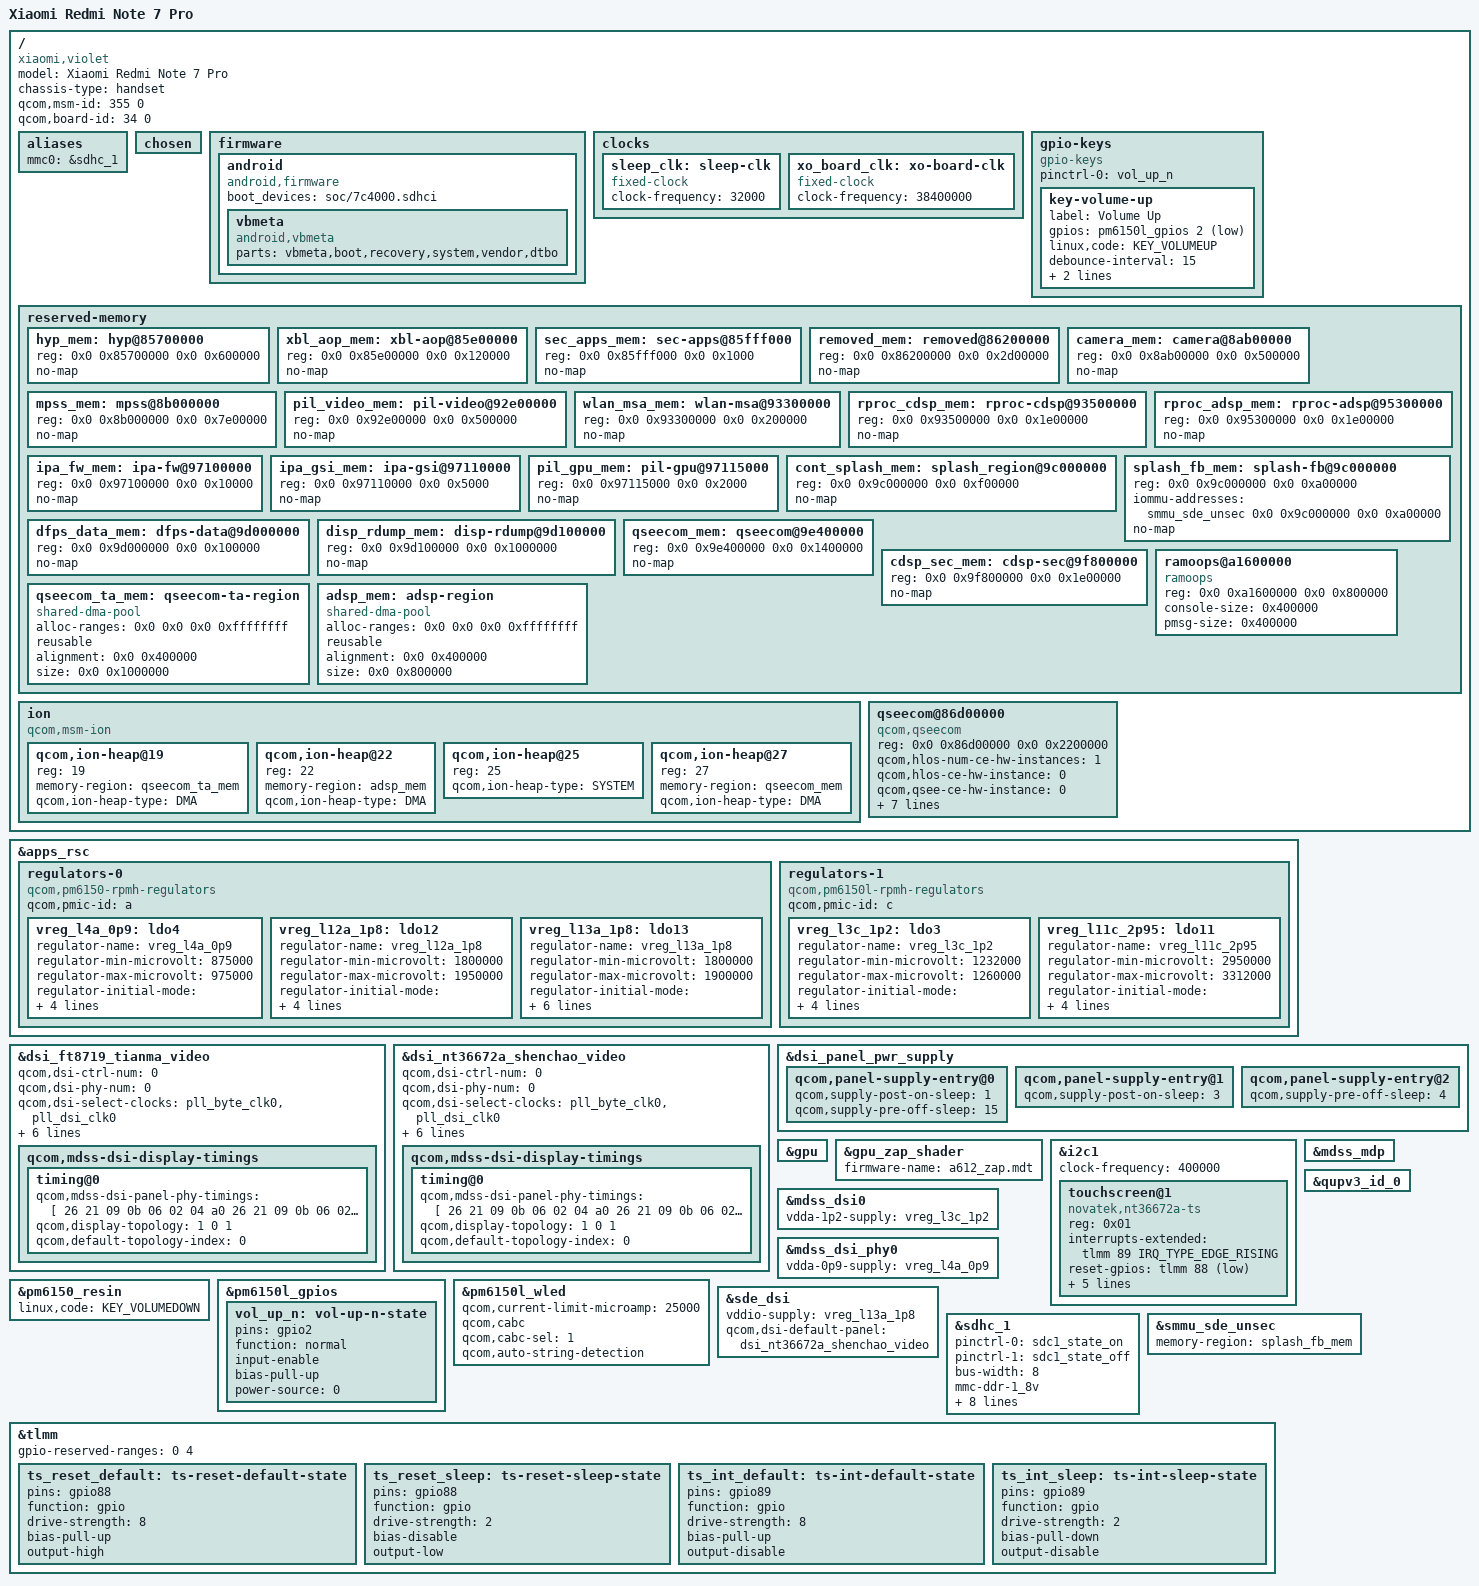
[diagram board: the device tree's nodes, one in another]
// SPDX-License-Identifier: BSD-3-Clause
/*
 * Xiaomi Redmi Note 7 Pro (violet)
 */

/dts-v1/;

#include <dt-bindings/gpio/gpio.h>
#include <dt-bindings/input/linux-event-codes.h>
#include <dt-bindings/regulator/qcom,rpmh-regulator.h>
#include "sm6150.dtsi"
#include "pm6150.dtsi"
#include "pm6150l.dtsi"
#include "sm6150-sde.dtsi"
#include "dsi-panel-ft8719-tianma-fhd-video.dtsi"
#include "dsi-panel-nt36672a-shenchao-fhd-video.dtsi"

/*
 * The GPU, video, CDSP and ADSP firmware regions sit lower on violet than on
 * QCS615; they are re-added below at the addresses violet's firmware uses.
 */
/delete-node/ &pil_gpu_mem;
/delete-node/ &pil_video_mem;
/delete-node/ &rproc_cdsp_mem;
/delete-node/ &rproc_adsp_mem;

/ {
	model = "Xiaomi Redmi Note 7 Pro";
	compatible = "xiaomi,violet", "qcom,sm6150";
	chassis-type = "handset";

	/* The msm-4.14 bootloader picks the DTB by these */
	qcom,msm-id = <355 0>;
	qcom,board-id = <34 0>;

	aliases {
		mmc0 = &sdhc_1;
	};

	chosen {
	};

	firmware {
		android {
			compatible = "android,firmware";
			boot_devices = "soc/7c4000.sdhci";

			vbmeta {
				compatible = "android,vbmeta";
				parts = "vbmeta,boot,recovery,system,vendor,dtbo";
			};
		};
	};

	clocks {
		sleep_clk: sleep-clk {
			compatible = "fixed-clock";
			clock-frequency = <32000>;
			#clock-cells = <0>;
		};

		xo_board_clk: xo-board-clk {
			compatible = "fixed-clock";
			clock-frequency = <38400000>;
			#clock-cells = <0>;
		};
	};

	gpio-keys {
		compatible = "gpio-keys";

		pinctrl-0 = <&vol_up_n>;
		pinctrl-names = "default";

		key-volume-up {
			label = "Volume Up";
			gpios = <&pm6150l_gpios 2 GPIO_ACTIVE_LOW>;
			linux,code = <KEY_VOLUMEUP>;
			debounce-interval = <15>;
			linux,can-disable;
			wakeup-source;
		};
	};

	reserved-memory {
		hyp_mem: hyp@85700000 {
			reg = <0x0 0x85700000 0x0 0x600000>;
			no-map;
		};

		xbl_aop_mem: xbl-aop@85e00000 {
			reg = <0x0 0x85e00000 0x0 0x120000>;
			no-map;
		};

		sec_apps_mem: sec-apps@85fff000 {
			reg = <0x0 0x85fff000 0x0 0x1000>;
			no-map;
		};

		removed_mem: removed@86200000 {
			reg = <0x0 0x86200000 0x0 0x2d00000>;
			no-map;
		};

		camera_mem: camera@8ab00000 {
			reg = <0x0 0x8ab00000 0x0 0x500000>;
			no-map;
		};

		mpss_mem: mpss@8b000000 {
			reg = <0x0 0x8b000000 0x0 0x7e00000>;
			no-map;
		};

		pil_video_mem: pil-video@92e00000 {
			reg = <0x0 0x92e00000 0x0 0x500000>;
			no-map;
		};

		wlan_msa_mem: wlan-msa@93300000 {
			reg = <0x0 0x93300000 0x0 0x200000>;
			no-map;
		};

		rproc_cdsp_mem: rproc-cdsp@93500000 {
			reg = <0x0 0x93500000 0x0 0x1e00000>;
			no-map;
		};

		rproc_adsp_mem: rproc-adsp@95300000 {
			reg = <0x0 0x95300000 0x0 0x1e00000>;
			no-map;
		};

		ipa_fw_mem: ipa-fw@97100000 {
			reg = <0x0 0x97100000 0x0 0x10000>;
			no-map;
		};

		ipa_gsi_mem: ipa-gsi@97110000 {
			reg = <0x0 0x97110000 0x0 0x5000>;
			no-map;
		};

		pil_gpu_mem: pil-gpu@97115000 {
			reg = <0x0 0x97115000 0x0 0x2000>;
			no-map;
		};

		/*
		 * The bootloader looks this node up by name and rewrites its
		 * size to the framebuffer it leaves on screen.
		 */
		cont_splash_mem: splash_region@9c000000 {
			reg = <0x0 0x9c000000 0x0 0xf00000>;
			no-map;
		};

		/*
		 * The framebuffer the bootloader leaves on screen, mapped 1:1
		 * for the display from the moment the IOMMU takes it over.
		 */
		splash_fb_mem: splash-fb@9c000000 {
			reg = <0x0 0x9c000000 0x0 0xa00000>;
			iommu-addresses = <&smmu_sde_unsec 0x0 0x9c000000 0x0 0xa00000>;
			no-map;
		};

		dfps_data_mem: dfps-data@9d000000 {
			reg = <0x0 0x9d000000 0x0 0x100000>;
			no-map;
		};

		disp_rdump_mem: disp-rdump@9d100000 {
			reg = <0x0 0x9d100000 0x0 0x1000000>;
			no-map;
		};

		qseecom_mem: qseecom@9e400000 {
			reg = <0x0 0x9e400000 0x0 0x1400000>;
			no-map;
		};

		cdsp_sec_mem: cdsp-sec@9f800000 {
			reg = <0x0 0x9f800000 0x0 0x1e00000>;
			no-map;
		};

		ramoops@a1600000 {
			compatible = "ramoops";
			reg = <0x0 0xa1600000 0x0 0x800000>;
			console-size = <0x400000>;
			pmsg-size = <0x400000>;
		};

		qseecom_ta_mem: qseecom-ta-region {
			compatible = "shared-dma-pool";
			alloc-ranges = <0x0 0x0 0x0 0xffffffff>;
			reusable;
			alignment = <0x0 0x400000>;
			size = <0x0 0x1000000>;
		};

		adsp_mem: adsp-region {
			compatible = "shared-dma-pool";
			alloc-ranges = <0x0 0x0 0x0 0xffffffff>;
			reusable;
			alignment = <0x0 0x400000>;
			size = <0x0 0x800000>;
		};
	};

	/* /dev/ion, with the heap IDs violet's vendor HALs were built for */
	ion {
		compatible = "qcom,msm-ion";
		#address-cells = <1>;
		#size-cells = <0>;

		qcom,ion-heap@19 {
			reg = <19>;
			memory-region = <&qseecom_ta_mem>;
			qcom,ion-heap-type = "DMA";
		};

		qcom,ion-heap@22 {
			reg = <22>;
			memory-region = <&adsp_mem>;
			qcom,ion-heap-type = "DMA";
		};

		qcom,ion-heap@25 {
			reg = <25>;
			qcom,ion-heap-type = "SYSTEM";
		};

		qcom,ion-heap@27 {
			reg = <27>;
			memory-region = <&qseecom_mem>;
			qcom,ion-heap-type = "DMA";
		};
	};

	qseecom@86d00000 {
		compatible = "qcom,qseecom";
		reg = <0x0 0x86d00000 0x0 0x2200000>;
		reg-names = "secapp-region";
		qcom,hlos-num-ce-hw-instances = <1>;
		qcom,hlos-ce-hw-instance = <0>;
		qcom,qsee-ce-hw-instance = <0>;
		qcom,disk-encrypt-pipe-pair = <2>;
		qcom,support-fde;
		qcom,no-clock-support;
		qcom,fde-key-size;
		qcom,appsbl-qseecom-support;
		qcom,commonlib64-loaded-by-uefi;
		qcom,qsee-reentrancy-support = <2>;
	};
};

&apps_rsc {
	regulators-0 {
		compatible = "qcom,pm6150-rpmh-regulators";
		qcom,pmic-id = "a";

		vreg_l4a_0p9: ldo4 {
			regulator-name = "vreg_l4a_0p9";
			regulator-min-microvolt = <875000>;
			regulator-max-microvolt = <975000>;
			regulator-initial-mode = <RPMH_REGULATOR_MODE_HPM>;
			regulator-allow-set-load;
			regulator-allowed-modes = <RPMH_REGULATOR_MODE_LPM
						   RPMH_REGULATOR_MODE_HPM>;
		};

		vreg_l12a_1p8: ldo12 {
			regulator-name = "vreg_l12a_1p8";
			regulator-min-microvolt = <1800000>;
			regulator-max-microvolt = <1950000>;
			regulator-initial-mode = <RPMH_REGULATOR_MODE_HPM>;
			regulator-allow-set-load;
			regulator-allowed-modes = <RPMH_REGULATOR_MODE_LPM
						   RPMH_REGULATOR_MODE_HPM>;
		};

		/*
		 * The panel's and the touch's 1.8 V I/O, and the pull-ups of
		 * the touch I2C bus: keep it on, or the touch driver turns it
		 * off after probing, before the display has taken it.
		 */
		vreg_l13a_1p8: ldo13 {
			regulator-name = "vreg_l13a_1p8";
			regulator-min-microvolt = <1800000>;
			regulator-max-microvolt = <1900000>;
			regulator-initial-mode = <RPMH_REGULATOR_MODE_HPM>;
			regulator-boot-on;
			regulator-always-on;
			regulator-allow-set-load;
			regulator-allowed-modes = <RPMH_REGULATOR_MODE_LPM
						   RPMH_REGULATOR_MODE_HPM>;
		};
	};

	regulators-1 {
		compatible = "qcom,pm6150l-rpmh-regulators";
		qcom,pmic-id = "c";

		vreg_l3c_1p2: ldo3 {
			regulator-name = "vreg_l3c_1p2";
			regulator-min-microvolt = <1232000>;
			regulator-max-microvolt = <1260000>;
			regulator-initial-mode = <RPMH_REGULATOR_MODE_HPM>;
			regulator-allow-set-load;
			regulator-allowed-modes = <RPMH_REGULATOR_MODE_LPM
						   RPMH_REGULATOR_MODE_HPM>;
		};

		vreg_l11c_2p95: ldo11 {
			regulator-name = "vreg_l11c_2p95";
			regulator-min-microvolt = <2950000>;
			regulator-max-microvolt = <3312000>;
			regulator-initial-mode = <RPMH_REGULATOR_MODE_HPM>;
			regulator-allow-set-load;
			regulator-allowed-modes = <RPMH_REGULATOR_MODE_LPM
						   RPMH_REGULATOR_MODE_HPM>;
		};
	};
};

/*
 * The bootloader names the panel it found in msm_drm.dsi_display0=, and
 * the driver looks it up by node name, so the panel nodes keep the names
 * the bootloader knows.
 */
&dsi_ft8719_tianma_video {
	qcom,dsi-ctrl-num = <0>;
	qcom,dsi-phy-num = <0>;
	qcom,dsi-select-clocks = "pll_byte_clk0", "pll_dsi_clk0";

	qcom,mdss-dsi-t-clk-post = <0x0f>;
	qcom,mdss-dsi-t-clk-pre = <0x37>;
	qcom,panel-supply-entries = <&dsi_panel_pwr_supply>;
	qcom,platform-te-gpio = <&tlmm 90 0>;
	qcom,platform-reset-gpio = <&tlmm 91 0>;

	qcom,mdss-dsi-display-timings {
		timing@0 {
			qcom,mdss-dsi-panel-phy-timings = [
				26 21 09 0b 06 02 04 a0
				26 21 09 0b 06 02 04 a0
				26 21 09 0b 06 02 04 a0
				26 21 09 0b 06 02 04 a0
				26 20 0a 0b 06 02 04 a0];
			qcom,display-topology = <1 0 1>;
			qcom,default-topology-index = <0>;
		};
	};
};

&dsi_nt36672a_shenchao_video {
	qcom,dsi-ctrl-num = <0>;
	qcom,dsi-phy-num = <0>;
	qcom,dsi-select-clocks = "pll_byte_clk0", "pll_dsi_clk0";

	qcom,mdss-dsi-t-clk-post = <0x0f>;
	qcom,mdss-dsi-t-clk-pre = <0x37>;
	qcom,panel-supply-entries = <&dsi_panel_pwr_supply>;
	qcom,platform-te-gpio = <&tlmm 90 0>;
	qcom,platform-reset-gpio = <&tlmm 91 0>;

	qcom,mdss-dsi-display-timings {
		timing@0 {
			qcom,mdss-dsi-panel-phy-timings = [
				26 21 09 0b 06 02 04 a0
				26 21 09 0b 06 02 04 a0
				26 21 09 0b 06 02 04 a0
				26 21 09 0b 06 02 04 a0
				26 20 0a 0b 06 02 04 a0];
			qcom,display-topology = <1 0 1>;
			qcom,default-topology-index = <0>;
		};
	};
};

/*
 * The panel power entries keep the lab and ibb names, but nothing drives
 * the PM6150L LCDB yet: those two fall back to dummy supplies, and the
 * LCDB stays on as the bootloader left it.
 */
&dsi_panel_pwr_supply {
	qcom,panel-supply-entry@0 {
		qcom,supply-post-on-sleep = <1>;
		qcom,supply-pre-off-sleep = <15>;
	};

	qcom,panel-supply-entry@1 {
		qcom,supply-post-on-sleep = <3>;
	};

	qcom,panel-supply-entry@2 {
		/delete-property/ qcom,supply-post-on-sleep;
		qcom,supply-pre-off-sleep = <4>;
	};
};

&gpu {
	status = "okay";
};

&gpu_zap_shader {
	/* The vendor partition has the zap shader split into segments */
	firmware-name = "a612_zap.mdt";
};

&i2c1 {
	clock-frequency = <400000>;
	status = "okay";

	/* The touch part of the NT36672A TDDI on the Shenchao panel */
	touchscreen@1 {
		compatible = "novatek,nt36672a-ts";
		reg = <0x01>;

		interrupts-extended = <&tlmm 89 IRQ_TYPE_EDGE_RISING>;
		reset-gpios = <&tlmm 88 GPIO_ACTIVE_LOW>;

		iovcc-supply = <&vreg_l13a_1p8>;

		pinctrl-0 = <&ts_int_default &ts_reset_default>;
		pinctrl-1 = <&ts_int_sleep &ts_reset_sleep>;
		pinctrl-names = "default", "sleep";

		touchscreen-size-x = <1080>;
		touchscreen-size-y = <2340>;
	};
};

&mdss_dsi0 {
	vdda-1p2-supply = <&vreg_l3c_1p2>;
	status = "okay";
};

&mdss_dsi_phy0 {
	vdda-0p9-supply = <&vreg_l4a_0p9>;
	status = "okay";
};

&mdss_mdp {
	status = "okay";
};

&pm6150_resin {
	linux,code = <KEY_VOLUMEDOWN>;
	status = "okay";
};

&pm6150l_gpios {
	vol_up_n: vol-up-n-state {
		pins = "gpio2";
		function = "normal";
		input-enable;
		bias-pull-up;
		power-source = <0>;
	};
};

&pm6150l_wled {
	qcom,current-limit-microamp = <25000>;
	qcom,cabc;
	qcom,cabc-sel = <1>;
	qcom,auto-string-detection;

	status = "okay";
};

&qupv3_id_0 {
	status = "okay";
};

&sde_dsi {
	vddio-supply = <&vreg_l13a_1p8>;

	/* Used when the bootloader does not name the panel */
	qcom,dsi-default-panel = <&dsi_nt36672a_shenchao_video>;

	status = "okay";
};

&sdhc_1 {
	pinctrl-0 = <&sdc1_state_on>;
	pinctrl-1 = <&sdc1_state_off>;
	pinctrl-names = "default", "sleep";

	bus-width = <8>;
	mmc-ddr-1_8v;
	mmc-hs200-1_8v;
	mmc-hs400-1_8v;
	mmc-hs400-enhanced-strobe;
	non-removable;
	no-sd;
	no-sdio;

	vmmc-supply = <&vreg_l11c_2p95>;
	vqmmc-supply = <&vreg_l12a_1p8>;

	status = "okay";
};

/*
 * GPIOs 0-3 belong to TrustZone: reading their configuration from Linux
 * raises an SError.
 */
&smmu_sde_unsec {
	memory-region = <&splash_fb_mem>;
	status = "okay";
};

&tlmm {
	gpio-reserved-ranges = <0 4>;

	ts_reset_default: ts-reset-default-state {
		pins = "gpio88";
		function = "gpio";
		drive-strength = <8>;
		bias-pull-up;
		output-high;
	};

	ts_reset_sleep: ts-reset-sleep-state {
		pins = "gpio88";
		function = "gpio";
		drive-strength = <2>;
		bias-disable;
		output-low;
	};

	ts_int_default: ts-int-default-state {
		pins = "gpio89";
		function = "gpio";
		drive-strength = <8>;
		bias-pull-up;
		output-disable;
	};

	ts_int_sleep: ts-int-sleep-state {
		pins = "gpio89";
		function = "gpio";
		drive-strength = <2>;
		bias-pull-down;
		output-disable;
	};
};
